# MSPM0G110X register map
Vendor: Texas Instruments; File version: This preliminary header file does not have a version number - build date: 2023-02-21 16:25:48
CPU: CM0 r0p1, little endian, MPU, no FPU, 3 interrupt priority bits
Registers are 32-bit, read-write, reset 0x0 unless marked. A register's access mark holds for its fields unless they carry their own. Offsets are from the block's base; [hi:lo] are bit positions.

## RTC — PERIPHERALREGION
Base 0x40094000
0x444 FPUB_0 — Publisher Port 0
  [3:0] FPUB_0_CHANID — 0 = disconnected. 1-15 = connected to channelID = CHANID.
    0=FPUB_0_CHANID_UNCONNECTED (UNCONNECTED)
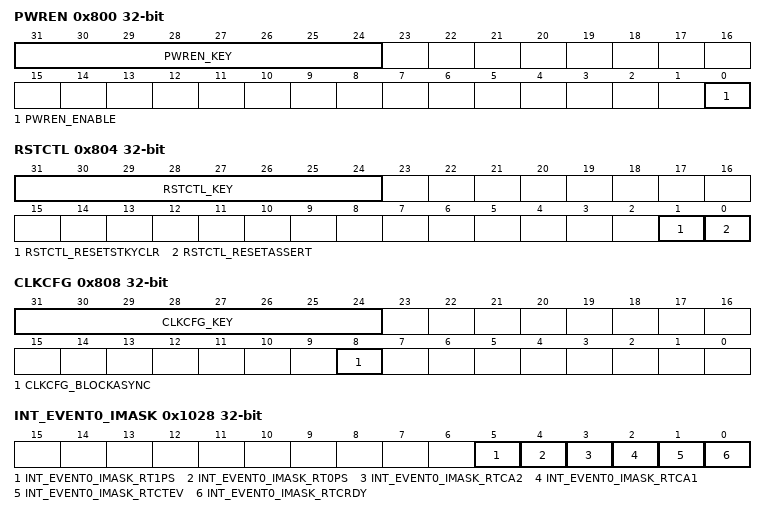
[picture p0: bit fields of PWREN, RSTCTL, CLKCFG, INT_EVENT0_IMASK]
0x800 PWREN — Power enable
  [31:24] PWREN_KEY wo — KEY to allow Power State Change
    38=PWREN_KEY_UNLOCK_W (_TO_UNLOCK_W_)
  [0] PWREN_ENABLE — Enable the power
    0=PWREN_ENABLE_DISABLE (DISABLE); 1=PWREN_ENABLE_ENABLE (ENABLE)
0x804 RSTCTL wo — Reset Control
  [31:24] RSTCTL_KEY — Unlock key
    177=RSTCTL_KEY_UNLOCK_W (_TO_UNLOCK_W_)
  [1] RSTCTL_RESETSTKYCLR — Clear the RESETSTKY bit in the STAT register
    0=RSTCTL_RESETSTKYCLR_NOP (NOP); 1=RSTCTL_RESETSTKYCLR_CLR (CLR)
  [0] RSTCTL_RESETASSERT — Assert reset to the peripheral
    0=RSTCTL_RESETASSERT_NOP (NOP); 1=RSTCTL_RESETASSERT_ASSERT (ASSERT)
0x808 CLKCFG — Peripheral Clock Configuration Register
  [31:24] CLKCFG_KEY wo — KEY to Allow State Change -- 0xA9
    169=CLKCFG_KEY_UNLOCK_W (_TO_UNLOCK_W_)
  [8] CLKCFG_BLOCKASYNC — Async Clock Request is blocked from starting SYSOSC or forcing bus clock to 32MHz
    0=CLKCFG_BLOCKASYNC_DISABLE (DISABLE); 1=CLKCFG_BLOCKASYNC_ENABLE (ENABLE)
0x814 STAT ro — Status Register
  [16] STAT_RESETSTKY — This bit indicates, if the peripheral was reset, since this bit was cleared by RESETSTKYCLR in the RSTCTL register
    0=STAT_RESETSTKY_NORES (NORES); 1=STAT_RESETSTKY_RESET (RESET)
0x1004 CLKSEL ro — Clock Select for Ultra Low Power peripherals
  [1] CLKSEL_LFCLK_SEL — Selects LFCLK as clock source if enabled
    0=CLKSEL_LFCLK_SEL_DISABLE (DISABLE); 1=CLKSEL_LFCLK_SEL_ENABLE (ENABLE)
0x1020 INT_EVENT0_IIDX ro — Interrupt Index Register
  [7:0] INT_EVENT0_IIDX_STAT — Interrupt index status
    0=INT_EVENT0_IIDX_STAT_NO_INTR (NO_INTR); 1=INT_EVENT0_IIDX_STAT_RTCRDY (RTCRDY); 2=INT_EVENT0_IIDX_STAT_RTCTEV (RTCTEV); 3=INT_EVENT0_IIDX_STAT_RTCA1 (RTCA1); 4=INT_EVENT0_IIDX_STAT_RTCA2 (RTCA2); 5=INT_EVENT0_IIDX_STAT_RT0PS (RT0PS); 6=INT_EVENT0_IIDX_STAT_RT1PS (RT1PS)
0x1028 INT_EVENT0_IMASK — Interrupt mask
  [5] INT_EVENT0_IMASK_RT1PS — Enable Prescaler-1 interrupt
    0=INT_EVENT0_IMASK_RT1PS_CLR (CLR); 1=INT_EVENT0_IMASK_RT1PS_SET (SET)
  [4] INT_EVENT0_IMASK_RT0PS — Enable Prescaler-0 interrupt
    0=INT_EVENT0_IMASK_RT0PS_CLR (CLR); 1=INT_EVENT0_IMASK_RT0PS_SET (SET)
  [3] INT_EVENT0_IMASK_RTCA2 — Enable Alarm-2 interrupt
    0=INT_EVENT0_IMASK_RTCA2_CLR (CLR); 1=INT_EVENT0_IMASK_RTCA2_SET (SET)
  [2] INT_EVENT0_IMASK_RTCA1 — Enable Alarm-1 interrupt
    0=INT_EVENT0_IMASK_RTCA1_CLR (CLR); 1=INT_EVENT0_IMASK_RTCA1_SET (SET)
  [1] INT_EVENT0_IMASK_RTCTEV — Enable Time-Event interrupt
    0=INT_EVENT0_IMASK_RTCTEV_CLR (CLR); 1=INT_EVENT0_IMASK_RTCTEV_SET (SET)
  [0] INT_EVENT0_IMASK_RTCRDY — Enable RTC-Ready interrupt
    0=INT_EVENT0_IMASK_RTCRDY_CLR (CLR); 1=INT_EVENT0_IMASK_RTCRDY_SET (SET)
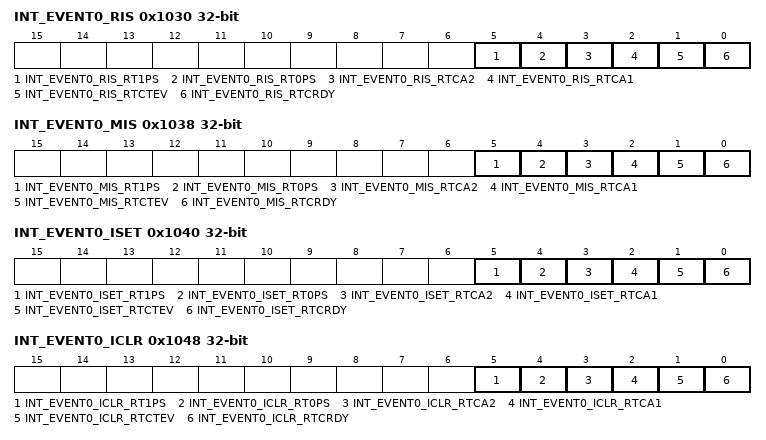
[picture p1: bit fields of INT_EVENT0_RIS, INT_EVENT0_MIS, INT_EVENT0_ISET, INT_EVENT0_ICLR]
0x1030 INT_EVENT0_RIS ro — Raw interrupt status
  [5] INT_EVENT0_RIS_RT1PS — Raw Prescaler-1 interrupt status
    0=INT_EVENT0_RIS_RT1PS_CLR (CLR); 1=INT_EVENT0_RIS_RT1PS_SET (SET)
  [4] INT_EVENT0_RIS_RT0PS — Raw Prescaler-0 interrupt status
    0=INT_EVENT0_RIS_RT0PS_CLR (CLR); 1=INT_EVENT0_RIS_RT0PS_SET (SET)
  [3] INT_EVENT0_RIS_RTCA2 — Raw Alarm-2 interrupts status
    0=INT_EVENT0_RIS_RTCA2_CLR (CLR); 1=INT_EVENT0_RIS_RTCA2_SET (SET)
  [2] INT_EVENT0_RIS_RTCA1 — Raw Alarm-1 interrupt status
    0=INT_EVENT0_RIS_RTCA1_CLR (CLR); 1=INT_EVENT0_RIS_RTCA1_SET (SET)
  [1] INT_EVENT0_RIS_RTCTEV — Raw Time-Event interrupt status
    0=INT_EVENT0_RIS_RTCTEV_CLR (CLR); 1=INT_EVENT0_RIS_RTCTEV_SET (SET)
  [0] INT_EVENT0_RIS_RTCRDY — Raw RTC-Ready interrupts status
    0=INT_EVENT0_RIS_RTCRDY_CLR (CLR); 1=INT_EVENT0_RIS_RTCRDY_SET (SET)
0x1038 INT_EVENT0_MIS ro — Masked interrupt status
  [5] INT_EVENT0_MIS_RT1PS — Masked Prescaler-1 interrupt status
    0=INT_EVENT0_MIS_RT1PS_CLR (CLR); 1=INT_EVENT0_MIS_RT1PS_SET (SET)
  [4] INT_EVENT0_MIS_RT0PS — Masked Prescaler-0 interrupt status
    0=INT_EVENT0_MIS_RT0PS_CLR (CLR); 1=INT_EVENT0_MIS_RT0PS_SET (SET)
  [3] INT_EVENT0_MIS_RTCA2 — Masked Alarm-2 interrupt status
    0=INT_EVENT0_MIS_RTCA2_CLR (CLR); 1=INT_EVENT0_MIS_RTCA2_SET (SET)
  [2] INT_EVENT0_MIS_RTCA1 — Masked Alarm-1 interrupt status
    0=INT_EVENT0_MIS_RTCA1_CLR (CLR); 1=INT_EVENT0_MIS_RTCA1_SET (SET)
  [1] INT_EVENT0_MIS_RTCTEV — Masked Time-Event interrupt status
    0=INT_EVENT0_MIS_RTCTEV_CLR (CLR); 1=INT_EVENT0_MIS_RTCTEV_SET (SET)
  [0] INT_EVENT0_MIS_RTCRDY — Masked RTC-Ready interrupt status
    0=INT_EVENT0_MIS_RTCRDY_CLR (CLR); 1=INT_EVENT0_MIS_RTCRDY_SET (SET)
0x1040 INT_EVENT0_ISET wo — Interrupt set
  [5] INT_EVENT0_ISET_RT1PS — Set Prescaler-1 interrupt
    0=INT_EVENT0_ISET_RT1PS_CLR (CLR); 1=INT_EVENT0_ISET_RT1PS_SET (SET)
  [4] INT_EVENT0_ISET_RT0PS — Set Prescaler-0 interrupt
    0=INT_EVENT0_ISET_RT0PS_CLR (CLR); 1=INT_EVENT0_ISET_RT0PS_SET (SET)
  [3] INT_EVENT0_ISET_RTCA2 — Set Alarm-2 interrupt
    0=INT_EVENT0_ISET_RTCA2_CLR (CLR); 1=INT_EVENT0_ISET_RTCA2_SET (SET)
  [2] INT_EVENT0_ISET_RTCA1 — Set Alarm-1 interrupt
    0=INT_EVENT0_ISET_RTCA1_CLR (CLR); 1=INT_EVENT0_ISET_RTCA1_SET (SET)
  [1] INT_EVENT0_ISET_RTCTEV — Set Time-Event interrupt
    0=INT_EVENT0_ISET_RTCTEV_CLR (CLR); 1=INT_EVENT0_ISET_RTCTEV_SET (SET)
  [0] INT_EVENT0_ISET_RTCRDY — Set RTC-Ready interrupt
    0=INT_EVENT0_ISET_RTCRDY_CLR (CLR); 1=INT_EVENT0_ISET_RTCRDY_SET (SET)
0x1048 INT_EVENT0_ICLR wo — Interrupt clear
  [5] INT_EVENT0_ICLR_RT1PS — Clear Prescaler-1 interrupt
    0=INT_EVENT0_ICLR_RT1PS_CLR (CLR); 1=INT_EVENT0_ICLR_RT1PS_SET (SET)
  [4] INT_EVENT0_ICLR_RT0PS — Clear Prescaler-0 interrupt
    0=INT_EVENT0_ICLR_RT0PS_CLR (CLR); 1=INT_EVENT0_ICLR_RT0PS_SET (SET)
  [3] INT_EVENT0_ICLR_RTCA2 — Clear Alarm-2 interrupt
    0=INT_EVENT0_ICLR_RTCA2_CLR (CLR); 1=INT_EVENT0_ICLR_RTCA2_SET (SET)
  [2] INT_EVENT0_ICLR_RTCA1 — Clear Alarm-1 interrupt
    0=INT_EVENT0_ICLR_RTCA1_CLR (CLR); 1=INT_EVENT0_ICLR_RTCA1_SET (SET)
  [1] INT_EVENT0_ICLR_RTCTEV — Clear Time-Event interrupt
    0=INT_EVENT0_ICLR_RTCTEV_CLR (CLR); 1=INT_EVENT0_ICLR_RTCTEV_SET (SET)
  [0] INT_EVENT0_ICLR_RTCRDY — Clear RTC-Ready interrupt
    0=INT_EVENT0_ICLR_RTCRDY_CLR (CLR); 1=INT_EVENT0_ICLR_RTCRDY_SET (SET)
0x1050 INT_EVENT1_IIDX ro — Interrupt Index Register
  [7:0] INT_EVENT1_IIDX_STAT — Interrupt index status
    0=INT_EVENT1_IIDX_STAT_NO_INTR (NO_INTR); 1=INT_EVENT1_IIDX_STAT_RTCRDY (RTCRDY); 2=INT_EVENT1_IIDX_STAT_RTCTEV (RTCTEV); 3=INT_EVENT1_IIDX_STAT_RTCA1 (RTCA1); 4=INT_EVENT1_IIDX_STAT_RTCA2 (RTCA2); 5=INT_EVENT1_IIDX_STAT_RT0PS (RT0PS); 6=INT_EVENT1_IIDX_STAT_RT1PS (RT1PS)
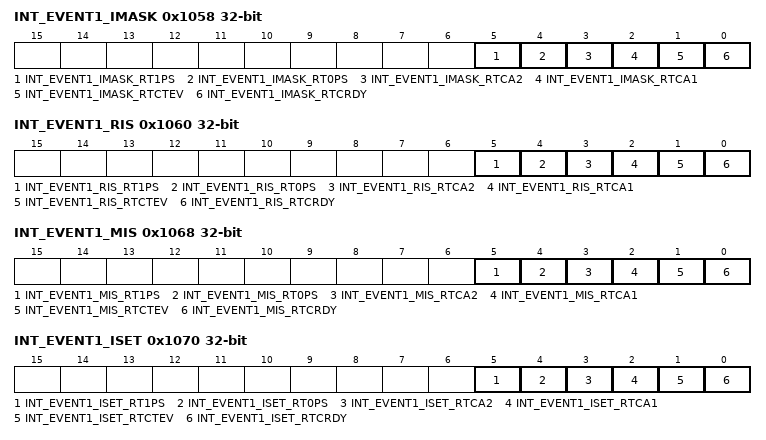
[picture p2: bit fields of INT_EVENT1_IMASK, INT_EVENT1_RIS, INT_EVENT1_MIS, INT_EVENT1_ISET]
0x1058 INT_EVENT1_IMASK — Interrupt mask
  [5] INT_EVENT1_IMASK_RT1PS — Enable Prescaler-1 interrupt
    0=INT_EVENT1_IMASK_RT1PS_CLR (CLR); 1=INT_EVENT1_IMASK_RT1PS_SET (SET)
  [4] INT_EVENT1_IMASK_RT0PS — Enable Prescaler-0 interrupt
    0=INT_EVENT1_IMASK_RT0PS_CLR (CLR); 1=INT_EVENT1_IMASK_RT0PS_SET (SET)
  [3] INT_EVENT1_IMASK_RTCA2 — Enable Alarm-2 interrupt
    0=INT_EVENT1_IMASK_RTCA2_CLR (CLR); 1=INT_EVENT1_IMASK_RTCA2_SET (SET)
  [2] INT_EVENT1_IMASK_RTCA1 — Enable Alarm-1 interrupt
    0=INT_EVENT1_IMASK_RTCA1_CLR (CLR); 1=INT_EVENT1_IMASK_RTCA1_SET (SET)
  [1] INT_EVENT1_IMASK_RTCTEV — Enable Time-Event interrupt
    0=INT_EVENT1_IMASK_RTCTEV_CLR (CLR); 1=INT_EVENT1_IMASK_RTCTEV_SET (SET)
  [0] INT_EVENT1_IMASK_RTCRDY — Enable RTC-Ready interrupt
    0=INT_EVENT1_IMASK_RTCRDY_CLR (CLR); 1=INT_EVENT1_IMASK_RTCRDY_SET (SET)
0x1060 INT_EVENT1_RIS ro — Raw interrupt status
  [5] INT_EVENT1_RIS_RT1PS — Raw Prescaler-1 interrupt status
    0=INT_EVENT1_RIS_RT1PS_CLR (CLR); 1=INT_EVENT1_RIS_RT1PS_SET (SET)
  [4] INT_EVENT1_RIS_RT0PS — Raw Prescaler-0 interrupt status
    0=INT_EVENT1_RIS_RT0PS_CLR (CLR); 1=INT_EVENT1_RIS_RT0PS_SET (SET)
  [3] INT_EVENT1_RIS_RTCA2 — Raw Alarm-2 interrupts status
    0=INT_EVENT1_RIS_RTCA2_CLR (CLR); 1=INT_EVENT1_RIS_RTCA2_SET (SET)
  [2] INT_EVENT1_RIS_RTCA1 — Raw Alarm-1 interrupt status
    0=INT_EVENT1_RIS_RTCA1_CLR (CLR); 1=INT_EVENT1_RIS_RTCA1_SET (SET)
  [1] INT_EVENT1_RIS_RTCTEV — Raw Time-Event interrupt status
    0=INT_EVENT1_RIS_RTCTEV_CLR (CLR); 1=INT_EVENT1_RIS_RTCTEV_SET (SET)
  [0] INT_EVENT1_RIS_RTCRDY — Raw RTC-Ready interrupts status
    0=INT_EVENT1_RIS_RTCRDY_CLR (CLR); 1=INT_EVENT1_RIS_RTCRDY_SET (SET)
0x1068 INT_EVENT1_MIS ro — Masked interrupt status
  [5] INT_EVENT1_MIS_RT1PS — Masked Prescaler-1 interrupt status
    0=INT_EVENT1_MIS_RT1PS_CLR (CLR); 1=INT_EVENT1_MIS_RT1PS_SET (SET)
  [4] INT_EVENT1_MIS_RT0PS — Masked Prescaler-0 interrupt status
    0=INT_EVENT1_MIS_RT0PS_CLR (CLR); 1=INT_EVENT1_MIS_RT0PS_SET (SET)
  [3] INT_EVENT1_MIS_RTCA2 — Masked Alarm-2 interrupt status
    0=INT_EVENT1_MIS_RTCA2_CLR (CLR); 1=INT_EVENT1_MIS_RTCA2_SET (SET)
  [2] INT_EVENT1_MIS_RTCA1 — Masked Alarm-1 interrupt status
    0=INT_EVENT1_MIS_RTCA1_CLR (CLR); 1=INT_EVENT1_MIS_RTCA1_SET (SET)
  [1] INT_EVENT1_MIS_RTCTEV — Masked Time-Event interrupt status
    0=INT_EVENT1_MIS_RTCTEV_CLR (CLR); 1=INT_EVENT1_MIS_RTCTEV_SET (SET)
  [0] INT_EVENT1_MIS_RTCRDY — Masked RTC-Ready interrupt status
    0=INT_EVENT1_MIS_RTCRDY_CLR (CLR); 1=INT_EVENT1_MIS_RTCRDY_SET (SET)
0x1070 INT_EVENT1_ISET wo — Interrupt set
  [5] INT_EVENT1_ISET_RT1PS — Set Prescaler-1 interrupt
    0=INT_EVENT1_ISET_RT1PS_CLR (CLR); 1=INT_EVENT1_ISET_RT1PS_SET (SET)
  [4] INT_EVENT1_ISET_RT0PS — Set Prescaler-0 interrupt
    0=INT_EVENT1_ISET_RT0PS_CLR (CLR); 1=INT_EVENT1_ISET_RT0PS_SET (SET)
  [3] INT_EVENT1_ISET_RTCA2 — Set Alarm-2 interrupt
    0=INT_EVENT1_ISET_RTCA2_CLR (CLR); 1=INT_EVENT1_ISET_RTCA2_SET (SET)
  [2] INT_EVENT1_ISET_RTCA1 — Set Alarm-1 interrupt
    0=INT_EVENT1_ISET_RTCA1_CLR (CLR); 1=INT_EVENT1_ISET_RTCA1_SET (SET)
  [1] INT_EVENT1_ISET_RTCTEV — Set Time-Event interrupt
    0=INT_EVENT1_ISET_RTCTEV_CLR (CLR); 1=INT_EVENT1_ISET_RTCTEV_SET (SET)
  [0] INT_EVENT1_ISET_RTCRDY — Set RTC-Ready interrupt
    0=INT_EVENT1_ISET_RTCRDY_CLR (CLR); 1=INT_EVENT1_ISET_RTCRDY_SET (SET)
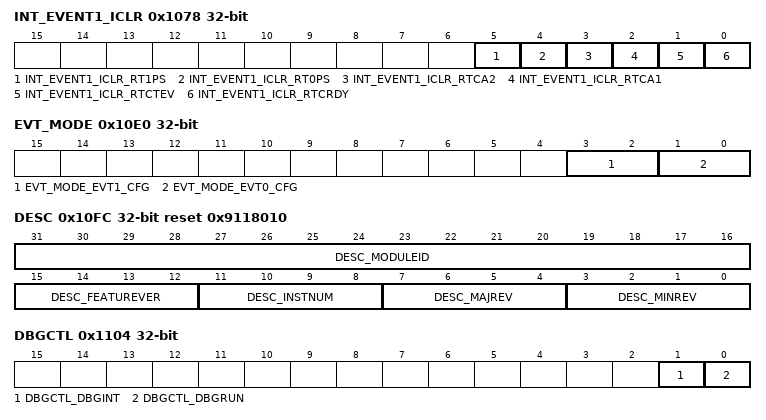
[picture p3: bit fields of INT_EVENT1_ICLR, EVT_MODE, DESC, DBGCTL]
0x1078 INT_EVENT1_ICLR wo — Interrupt clear
  [5] INT_EVENT1_ICLR_RT1PS — Clear Prescaler-1 interrupt
    0=INT_EVENT1_ICLR_RT1PS_CLR (CLR); 1=INT_EVENT1_ICLR_RT1PS_SET (SET)
  [4] INT_EVENT1_ICLR_RT0PS — Clear Prescaler-0 interrupt
    0=INT_EVENT1_ICLR_RT0PS_CLR (CLR); 1=INT_EVENT1_ICLR_RT0PS_SET (SET)
  [3] INT_EVENT1_ICLR_RTCA2 — Clear Alarm-2 interrupt
    0=INT_EVENT1_ICLR_RTCA2_CLR (CLR); 1=INT_EVENT1_ICLR_RTCA2_SET (SET)
  [2] INT_EVENT1_ICLR_RTCA1 — Clear Alarm-1 interrupt
    0=INT_EVENT1_ICLR_RTCA1_CLR (CLR); 1=INT_EVENT1_ICLR_RTCA1_SET (SET)
  [1] INT_EVENT1_ICLR_RTCTEV — Clear Time-Event interrupt
    0=INT_EVENT1_ICLR_RTCTEV_CLR (CLR); 1=INT_EVENT1_ICLR_RTCTEV_SET (SET)
  [0] INT_EVENT1_ICLR_RTCRDY — Clear RTC-Ready interrupt
    0=INT_EVENT1_ICLR_RTCRDY_CLR (CLR); 1=INT_EVENT1_ICLR_RTCRDY_SET (SET)
0x10E0 EVT_MODE — Event Mode
  [3:2] EVT_MODE_EVT1_CFG ro — Event line mode 1 select
    0=EVT_MODE_EVT1_CFG_DISABLE (DISABLE); 1=EVT_MODE_EVT1_CFG_SOFTWARE (SOFTWARE); 2=EVT_MODE_EVT1_CFG_HARDWARE (HARDWARE)
  [1:0] EVT_MODE_EVT0_CFG ro — Event line mode 0 select
    0=EVT_MODE_EVT0_CFG_DISABLE (DISABLE); 1=EVT_MODE_EVT0_CFG_SOFTWARE (SOFTWARE); 2=EVT_MODE_EVT0_CFG_HARDWARE (HARDWARE)
0x10FC DESC ro reset 0x9118010 — RTC Descriptor Register
  [31:16] DESC_MODULEID — Module identifier. This ID is unique for each module. 0x0911 = Module ID of the RTC Module
  [15:12] DESC_FEATUREVER — Feature set of this module. Differentiates the complexity of the actually instantiated module if there are differences.
  [11:8] DESC_INSTNUM — Instantiated version. Describes which instance of the module accessed.
    0=DESC_INSTNUM_INST0 (INST0)
  [7:4] DESC_MAJREV — Major revision. This number holds the module revision and is incremented by the module developers. n = Major version (see device-specific data sheet)
  [3:0] DESC_MINREV — Minor revision. This number holds the module revision and is incremented by the module developers. n = Minor module revision (see device-specific data sheet)
0x1100 CLKCTL — RTC Clock Control Register
  [31] CLKCTL_MODCLKEN — This bit enables the supply of the 32kHz clock to the RTC. It will not power-up the 32kHz crystal oscillator this needs to be done in the Clock System Module.
    0=CLKCTL_MODCLKEN_DISABLE (DISABLE); 1=CLKCTL_MODCLKEN_ENABLE (ENABLE)
0x1104 DBGCTL — RTC Module Debug Control Register
  [1] DBGCTL_DBGINT — Debug Interrupt Enable.
    0=DBGCTL_DBGINT_OFF (OFF); 1=DBGCTL_DBGINT_ON (ON)
  [0] DBGCTL_DBGRUN — Debug Run.
    0=DBGCTL_DBGRUN_HALT (HALT); 1=DBGCTL_DBGRUN_RUN (RUN)
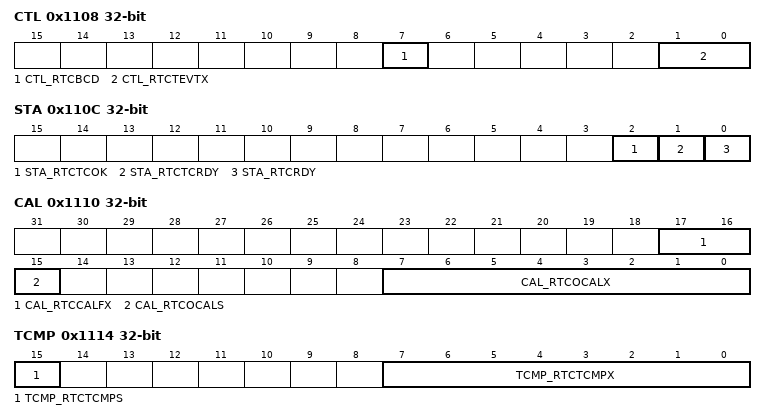
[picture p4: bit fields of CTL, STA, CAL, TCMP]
0x1108 CTL — RTC Control Register
  [7] CTL_RTCBCD — Real-time clock BCD select. Selects BCD counting for real-time clock.
    0=CTL_RTCBCD_BINARY (BINARY); 1=CTL_RTCBCD_BCD (BCD)
  [1:0] CTL_RTCTEVTX — Real-time clock time event.
    0=CTL_RTCTEVTX_MINUTE (MINUTE); 1=CTL_RTCTEVTX_HOUR (HOUR); 2=CTL_RTCTEVTX_MIDNIGHT (MIDNIGHT); 3=CTL_RTCTEVTX_NOON (NOON)
0x110C STA ro — RTC Status Register
  [2] STA_RTCTCOK — Real-time clock temperature compensation write OK. This is a read-only bit that indicates if the write to RTCTCMP is successful or not.
    0=STA_RTCTCOK_NOT_OK (NOT_OK); 1=STA_RTCTCOK_OK (OK)
  [1] STA_RTCTCRDY — Real-time clock temperature compensation ready. This is a read only bit that indicates when the RTCTCMPx can be written. Write to RTCTCMPx should be avoided when RTCTCRDY is reset.
    0=STA_RTCTCRDY_NOT_READY (NOT_READY); 1=STA_RTCTCRDY_READY (READY)
  [0] STA_RTCRDY — Real-time clock ready. This bit indicates when the real-time clock time values are safe for reading.
    0=STA_RTCRDY_NOT_READY (NOT_READY); 1=STA_RTCRDY_READY (READY)
0x1110 CAL — RTC Clock Offset Calibration Register
  [17:16] CAL_RTCCALFX — Real-time clock calibration frequency. Selects frequency output to RTC_OUT pin for calibration measurement. The corresponding port must be configured for the peripheral module function.
    0=CAL_RTCCALFX_OFF (OFF); 1=CAL_RTCCALFX_F512HZ (F512HZ); 2=CAL_RTCCALFX_F256HZ (F256HZ); 3=CAL_RTCCALFX_F1HZ (F1HZ)
  [15] CAL_RTCOCALS — Real-time clock offset error calibration sign. This bit decides the sign of offset error calibration.
    0=CAL_RTCOCALS_DOWN (DOWN); 1=CAL_RTCOCALS_UP (UP)
  [7:0] CAL_RTCOCALX — Real-time clock offset error calibration. Each LSB represents approximately +1ppm (RTCOCALXS = 1) or -1ppm (RTCOCALXS = 0) adjustment in frequency. Maximum effective calibration value is +/-240ppm. Excess values written above +/-240ppm will be ignored by hardware.
0x1114 TCMP — RTC Temperature Compensation Register
  [15] TCMP_RTCTCMPS — Real-time clock temperature compensation sign. This bit decides the sign of temperature compensation.
    0=TCMP_RTCTCMPS_DOWN (DOWN); 1=TCMP_RTCTCMPS_UP (UP)
  [7:0] TCMP_RTCTCMPX — Real-time clock temperature compensation. Value written into this register is used for temperature compensation of RTC. Each LSB represents approximately +1ppm (RTCTCMPS = 1) or -1ppm (RTCTCMPS = 0) adjustment in frequency. Maximum effective calibration value is +/-240ppm. Excess values written above +/-240ppm are ignored by hardware. Reading from RTCTCMP register at any time returns the cumulative value which is the signed addition of RTCOCALx and RTCTCMPX values, and the updated sign bit (RTCTCMPS) of the addition result.
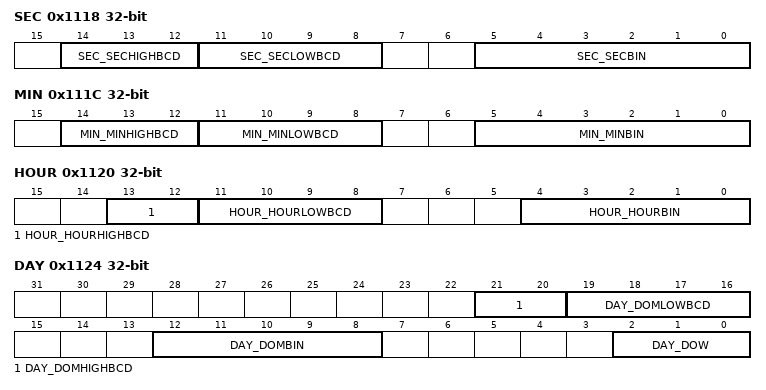
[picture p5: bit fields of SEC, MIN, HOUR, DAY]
0x1118 SEC (reset mask 0xFFFF80C0) — RTC Seconds Register - Calendar Mode With Binary / BCD Format
  [14:12] SEC_SECHIGHBCD — Seconds BCD high digit (0 to 5). If RTCBCD=0 write to these bits will be ignored and read give the value 0.
  [11:8] SEC_SECLOWBCD — Seconds BCD low digit (0 to 9). If RTCBCD=0 write to these bits will be ignored and read give the value 0.
  [5:0] SEC_SECBIN — Seconds Binary (0 to 59). If RTCBCD=1 write to these bits will be ignored and read give the value 0.
0x111C MIN (reset mask 0xFFFF80C0) — RTC Minutes Register - Calendar Mode With Binary / BCD Format
  [14:12] MIN_MINHIGHBCD — Minutes BCD high digit (0 to 5). If RTCBCD=0 write to these bits will be ignored and read give the value 0.
  [11:8] MIN_MINLOWBCD — Minutes BCD low digit (0 to 9). If RTCBCD=0 write to these bits will be ignored and read give the value 0.
  [5:0] MIN_MINBIN — Minutes Binary (0 to 59). If RTCBCD=1 write to these bits will be ignored and read give the value 0.
0x1120 HOUR (reset mask 0xFFFFC0E0) — RTC Hours Register - Calendar Mode With Binary / BCD Format
  [13:12] HOUR_HOURHIGHBCD — Hours BCD high digit (0 to 2). If RTCBCD=0 write to these bits will be ignored and read give the value 0.
  [11:8] HOUR_HOURLOWBCD — Hours BCD low digit (0 to 9). If RTCBCD=0 write to these bits will be ignored and read give the value 0.
  [4:0] HOUR_HOURBIN — Hours Binary (0 to 23). If RTCBCD=1 write to these bits will be ignored and read give the value 0.
0x1124 DAY (reset mask 0xFFC0E0F8) — RTC Day Of Week / Month Register - Calendar Mode With Binary / BCD Format
  [21:20] DAY_DOMHIGHBCD — Day of month BCD high digit (0 to 3). If RTCBCD=0 write to these bits will be ignored and read give the value 0.
  [19:16] DAY_DOMLOWBCD — Day of month BCD low digit (0 to 9). If RTCBCD=0 write to these bits will be ignored and read give the value 0.
  [12:8] DAY_DOMBIN — Day of month Binary (1 to 28, 29, 30, 31). If RTCBCD=1 write to these bits will be ignored and read give the value 0.
  [2:0] DAY_DOW — Day of week (0 to 6). These bits are valid if RTCBCD=1 or RTCBCD=0.
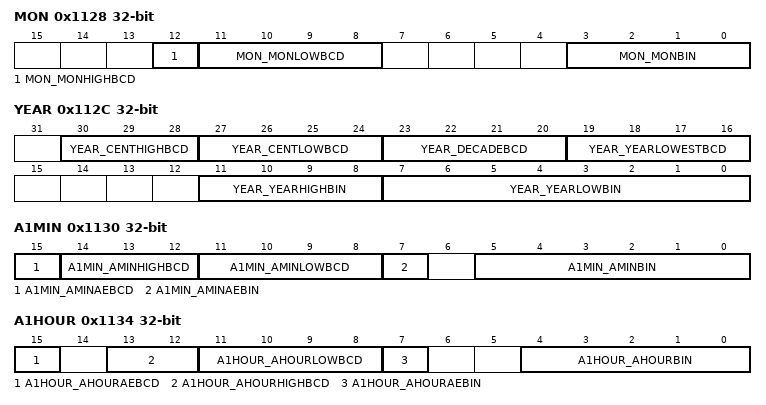
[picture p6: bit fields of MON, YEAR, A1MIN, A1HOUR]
0x1128 MON (reset mask 0xFFFFE0F0) — RTC Month Register - Calendar Mode With Binary / BCD Format
  [12] MON_MONHIGHBCD — Month BCD high digit (0 or 1). If RTCBCD=0 write to these bits will be ignored and read give the value 0.
  [11:8] MON_MONLOWBCD — Month BCD low digit (0 to 9). If RTCBCD=0 write to these bits will be ignored and read give the value 0.
  [3:0] MON_MONBIN — Month Binary (1 to 12). If RTCBCD=1 write to these bits will be ignored and read give the value 0.
0x112C YEAR (reset mask 0x8000F000) — RTC Year Register - Calendar Mode With Binary / BCD Format
  [30:28] YEAR_CENTHIGHBCD — Century BCD high digit (0 to 4). If RTCBCD=0 write to these bits will be ignored and read give the value 0.
  [27:24] YEAR_CENTLOWBCD — Century BCD low digit (0 to 9). If RTCBCD=0 write to these bits will be ignored and read give the value 0.
  [23:20] YEAR_DECADEBCD — Decade BCD (0 to 9). If RTCBCD=0 write to these bits will be ignored and read give the value 0.
  [19:16] YEAR_YEARLOWESTBCD — Year BCD lowest digit (0 to 9). If RTCBCD=0 write to these bits will be ignored and read give the value 0.
  [11:8] YEAR_YEARHIGHBIN — Year Binary high byte. Valid values for Year are 0 to 4095. If RTCBCD=1 write to these bits will be ignored and read give the value 0.
  [7:0] YEAR_YEARLOWBIN — Year Binary low byte. Valid values for Year are 0 to 4095. If RTCBCD=1 write to these bits will be ignored and read give the value 0.
0x1130 A1MIN — RTC Minute Alarm Register - Calendar Mode With Binary / BCD Format
  [15] A1MIN_AMINAEBCD — Alarm Minutes BCD enable. If RTCBCD=0 this bit is always 0. Write to this bit will be ignored.
    0=A1MIN_AMINAEBCD_DISABLE (DISABLE); 1=A1MIN_AMINAEBCD_ENABLE (ENABLE)
  [14:12] A1MIN_AMINHIGHBCD — Alarm Minutes BCD high digit (0 to 5). If RTCBCD=0 write to these bits will be ignored and read give the value 0.
  [11:8] A1MIN_AMINLOWBCD — Alarm Minutes BCD low digit (0 to 9). If RTCBCD=0 write to these bits will be ignored and read give the value 0.
  [7] A1MIN_AMINAEBIN — Alarm Minutes Binary enable. If RTCBCD=1 this bit is always 0. Write to this bit will be ignored.
    0=A1MIN_AMINAEBIN_DISABLE (DISABLE); 1=A1MIN_AMINAEBIN_ENABLE (ENABLE)
  [5:0] A1MIN_AMINBIN — Alarm Minutes Binary (0 to 59). If RTCBCD=1 write to these bits will be ignored and read give the value 0.
0x1134 A1HOUR — RTC Hours Alarm Register - Calendar Mode With Binary / BCD Format
  [15] A1HOUR_AHOURAEBCD — Alarm Hours BCD enable. If RTCBCD=0 this bit is always 0. Write to this bit will be ignored.
    0=A1HOUR_AHOURAEBCD_DISABLE (DISABLE); 1=A1HOUR_AHOURAEBCD_ENABLE (ENABLE)
  [13:12] A1HOUR_AHOURHIGHBCD — Alarm Hours BCD high digit (0 to 2). If RTCBCD=0 write to these bits will be ignored and read give the value 0..
  [11:8] A1HOUR_AHOURLOWBCD — Alarm Hours BCD low digit (0 to 9). If RTCBCD=0 write to these bits will be ignored and read give the value 0.
  [7] A1HOUR_AHOURAEBIN — Alarm Hours Binary enable. If RTCBCD=1 this bit is always 0. Write to this bit will be ignored.
    0=A1HOUR_AHOURAEBIN_DISABLE (DISABLE); 1=A1HOUR_AHOURAEBIN_ENABLE (ENABLE)
  [4:0] A1HOUR_AHOURBIN — Alarm Hours Binary (0 to 23). If RTCBCD=1 write to these bits will be ignored and read give the value 0.
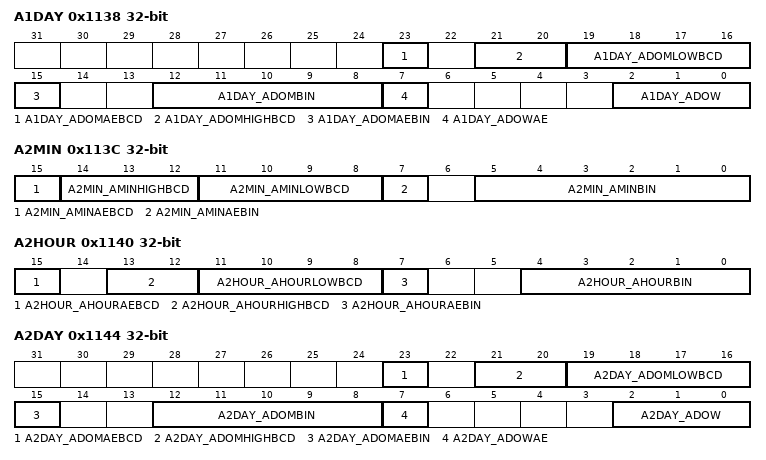
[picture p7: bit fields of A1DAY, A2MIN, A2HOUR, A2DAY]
0x1138 A1DAY — RTC Alarm Day Of Week / Month Register - Calendar Mode With Binary / BCD Format
  [23] A1DAY_ADOMAEBCD — Alarm Day of month BCD enable. If RTCBCD=0 this bit is always 0. Write to this bit will be ignored.
    0=A1DAY_ADOMAEBCD_DISABLE (DISABLE); 1=A1DAY_ADOMAEBCD_ENABLE (ENABLE)
  [21:20] A1DAY_ADOMHIGHBCD — Alarm Day of month BCD high digit (0 to 3). If RTCBCD=0 write to these bits will be ignored and read give the value 0.
  [19:16] A1DAY_ADOMLOWBCD — Alarm Day of month BCD low digit (0 to 9). If RTCBCD=0 write to these bits will be ignored and read give the value 0.
  [15] A1DAY_ADOMAEBIN — Alarm Day of month Binary enable. If RTCBCD=1 this bit is always 0. Write to this bit will be ignored.
    0=A1DAY_ADOMAEBIN_DISABLE (DISABLE); 1=A1DAY_ADOMAEBIN_ENABLE (ENABLE)
  [12:8] A1DAY_ADOMBIN — Alarm Day of month Binary (1 to 28, 29, 30, 31) If RTCBCD=1 write to these bits will be ignored and read give the value 0.
  [7] A1DAY_ADOWAE — Alarm Day of week enable. This bit are valid if RTCBCD=1 or RTCBCD=0.
    0=A1DAY_ADOWAE_DISABLE (DISABLE); 1=A1DAY_ADOWAE_ENABLE (ENABLE)
  [2:0] A1DAY_ADOW — Alarm Day of week (0 to 6). These bits are valid if RTCBCD=1 or RTCBCD=0.
0x113C A2MIN — RTC Minute Alarm Register - Calendar Mode With Binary / BCD Format
  [15] A2MIN_AMINAEBCD — Alarm Minutes BCD enable. If RTCBCD=0 this bit is always 0. Write to this bit will be ignored.
    0=A2MIN_AMINAEBCD_DISABLE (DISABLE); 1=A2MIN_AMINAEBCD_ENABLE (ENABLE)
  [14:12] A2MIN_AMINHIGHBCD — Alarm Minutes BCD high digit (0 to 5). If RTCBCD=0 write to these bits will be ignored and read give the value 0.
  [11:8] A2MIN_AMINLOWBCD — Alarm Minutes BCD low digit (0 to 9). If RTCBCD=0 write to these bits will be ignored and read give the value 0.
  [7] A2MIN_AMINAEBIN — Alarm Minutes Binary enable. If RTCBCD=1 this bit is always 0. Write to this bit will be ignored.
    0=A2MIN_AMINAEBIN_DISABLE (DISABLE); 1=A2MIN_AMINAEBIN_ENABLE (ENABLE)
  [5:0] A2MIN_AMINBIN — Alarm Minutes Binary (0 to 59). If RTCBCD=1 write to these bits will be ignored and read give the value 0.
0x1140 A2HOUR — RTC Hours Alarm Register - Calendar Mode With Binary / BCD Format
  [15] A2HOUR_AHOURAEBCD — Alarm Hours BCD enable. If RTCBCD=0 this bit is always 0. Write to this bit will be ignored.
    0=A2HOUR_AHOURAEBCD_DISABLE (DISABLE); 1=A2HOUR_AHOURAEBCD_ENABLE (ENABLE)
  [13:12] A2HOUR_AHOURHIGHBCD — Alarm Hours BCD high digit (0 to 2). If RTCBCD=0 write to these bits will be ignored and read give the value 0..
  [11:8] A2HOUR_AHOURLOWBCD — Alarm Hours BCD low digit (0 to 9). If RTCBCD=0 write to these bits will be ignored and read give the value 0.
  [7] A2HOUR_AHOURAEBIN — Alarm Hours Binary enable. If RTCBCD=1 this bit is always 0. Write to this bit will be ignored.
    0=A2HOUR_AHOURAEBIN_DISABLE (DISABLE); 1=A2HOUR_AHOURAEBIN_ENABLE (ENABLE)
  [4:0] A2HOUR_AHOURBIN — Alarm Hours Binary (0 to 23). If RTCBCD=1 write to these bits will be ignored and read give the value 0.
0x1144 A2DAY — RTC Alarm Day Of Week / Month Register - Calendar Mode With Binary / BCD Format
  [23] A2DAY_ADOMAEBCD — Alarm Day of month BCD enable. If RTCBCD=0 this bit is always 0. Write to this bit will be ignored.
    0=A2DAY_ADOMAEBCD_DISABLE (DISABLE); 1=A2DAY_ADOMAEBCD_ENABLE (ENABLE)
  [21:20] A2DAY_ADOMHIGHBCD — Alarm Day of month BCD high digit (0 to 3). If RTCBCD=0 write to these bits will be ignored and read give the value 0.
  [19:16] A2DAY_ADOMLOWBCD — Alarm Day of month BCD low digit (0 to 9). If RTCBCD=0 write to these bits will be ignored and read give the value 0.
  [15] A2DAY_ADOMAEBIN — Alarm Day of month Binary enable. If RTCBCD=1 this bit is always 0. Write to this bit will be ignored.
    0=A2DAY_ADOMAEBIN_DISABLE (DISABLE); 1=A2DAY_ADOMAEBIN_ENABLE (ENABLE)
  [12:8] A2DAY_ADOMBIN — Alarm Day of month Binary (1 to 28, 29, 30, 31) If RTCBCD=1 write to these bits will be ignored and read give the value 0.
  [7] A2DAY_ADOWAE — Alarm Day of week enable. This bit are valid if RTCBCD=1 or RTCBCD=0.
    0=A2DAY_ADOWAE_DISABLE (DISABLE); 1=A2DAY_ADOWAE_ENABLE (ENABLE)
  [2:0] A2DAY_ADOW — Alarm Day of week (0 to 6). These bits are valid if RTCBCD=1 or RTCBCD=0.
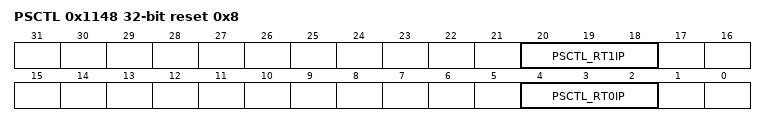
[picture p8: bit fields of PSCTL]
0x1148 PSCTL reset 0x8 — RTC Prescale Timer 0/1 Control Register
  [20:18] PSCTL_RT1IP — Prescale timer 1 interrupt interval
    0=PSCTL_RT1IP_DIV2 (DIV2); 1=PSCTL_RT1IP_DIV4 (DIV4); 2=PSCTL_RT1IP_DIV8 (DIV8); 3=PSCTL_RT1IP_DIV16 (DIV16); 4=PSCTL_RT1IP_DIV32 (DIV32); 5=PSCTL_RT1IP_DIV64 (DIV64); 6=PSCTL_RT1IP_DIV128 (DIV128); 7=PSCTL_RT1IP_DIV256 (DIV256)
  [4:2] PSCTL_RT0IP — Prescale timer 0 interrupt interval
    2=PSCTL_RT0IP_DIV8 (DIV8); 3=PSCTL_RT0IP_DIV16 (DIV16); 4=PSCTL_RT0IP_DIV32 (DIV32); 5=PSCTL_RT0IP_DIV64 (DIV64); 6=PSCTL_RT0IP_DIV128 (DIV128); 7=PSCTL_RT0IP_DIV256 (DIV256)
